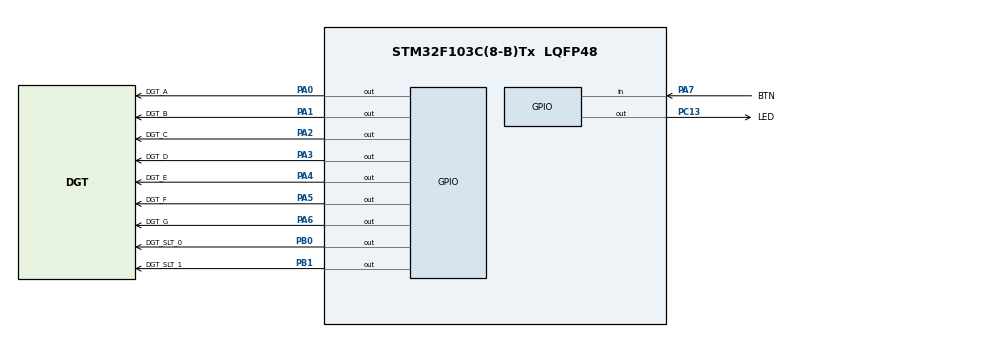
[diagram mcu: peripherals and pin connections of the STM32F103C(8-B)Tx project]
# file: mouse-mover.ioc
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Mcu.Family=STM32F1
Mcu.Name=STM32F103C(8-B)Tx
Mcu.Package=LQFP48
NVIC.PriorityGroup=NVIC_PRIORITYGROUP_4
NVIC.TIM2_IRQn=true\:0\:0\:false\:false\:true\:true\:true\:true
NVIC.TIM3_IRQn=true\:0\:0\:false\:false\:true\:true\:true\:true
PA0-WKUP.GPIO_Label=DGT_A
PA0-WKUP.Signal=GPIO_Output
PA1.GPIO_Label=DGT_B
PA1.Signal=GPIO_Output
PA13.Mode=Serial_Wire
PA13.Signal=SYS_JTMS-SWDIO
PA14.Mode=Serial_Wire
PA14.Signal=SYS_JTCK-SWCLK
PA2.GPIO_Label=DGT_C
PA2.Signal=GPIO_Output
PA3.GPIO_Label=DGT_D
PA3.Signal=GPIO_Output
PA4.GPIO_Label=DGT_E
PA4.Signal=GPIO_Output
PA5.GPIO_Label=DGT_F
PA5.Signal=GPIO_Output
PA6.GPIO_Label=DGT_G
PA6.Signal=GPIO_Output
PA7.GPIO_Label=BTN
PA7.GPIO_PuPd=GPIO_PULLUP
PA7.Signal=GPIO_Input
PB0.GPIO_Label=DGT_SLT_0
PB0.Signal=GPIO_Output
PB1.GPIO_Label=DGT_SLT_1
PB1.Signal=GPIO_Output
PC13-TAMPER-RTC.GPIO_Label=LED
PC13-TAMPER-RTC.Signal=GPIO_Output
ProjectManager.HeapSize=0x200
ProjectManager.StackSize=0x400
ProjectManager.TargetToolchain=CMake
RCC.APB1Freq_Value=8000000
RCC.APB2Freq_Value=8000000
TIM2.Period=999
TIM2.Prescaler=7999
TIM3.Period=9999
TIM3.Prescaler=7
VP_TIM2_VS_ClockSourceINT.Mode=Internal
VP_TIM3_VS_ClockSourceINT.Mode=Internal
board=custom

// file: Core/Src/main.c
/* USER CODE BEGIN Header */
/**
  ******************************************************************************
  * @file           : main.c
  * @brief          : Main program body
  ******************************************************************************
  * @attention
  *
  * Copyright (c) 2026 STMicroelectronics.
  * All rights reserved.
  *
  * This software is licensed under terms that can be found in the LICENSE file
  * in the root directory of this software component.
  * If no LICENSE file comes with this software, it is provided AS-IS.
  *
  ******************************************************************************
  */
/* USER CODE END Header */
#include "main.h"

/* USER CODE BEGIN Includes */
#include "app.h"
#include "bsp.h"
/* USER CODE END Includes */

TIM_HandleTypeDef htim2;
TIM_HandleTypeDef htim3;

void SystemClock_Config(void);
static void MX_GPIO_Init(void);
static void MX_TIM2_Init(void);
static void MX_TIM3_Init(void);

/* USER CODE BEGIN 0 */
void HAL_TIM_PeriodElapsedCallback(TIM_HandleTypeDef* htim)
{
  if (htim == &htim2)
  {
    app_countdown_tick_isr();
  }

  if (htim == &htim3)
  {
    app_display_tick_isr();
  }
}
/* USER CODE END 0 */

int main(void)
{

  /* MCU Configuration--------------------------------------------------------*/

  /* Reset of all peripherals, Initializes the Flash interface and the Systick. */
  HAL_Init();

  /* Configure the system clock */
  SystemClock_Config();

  /* Initialize all configured peripherals */
  MX_GPIO_Init();
  MX_TIM2_Init();
  MX_TIM3_Init();
  /* USER CODE BEGIN 2 */
  app_init();
  // A pending update flag would fire the first tick at once and the countdown would start one unit short.
  __HAL_TIM_CLEAR_FLAG(&htim2, TIM_FLAG_UPDATE);
  HAL_TIM_Base_Start_IT(&htim2);
  HAL_TIM_Base_Start_IT(&htim3);
  /* USER CODE END 2 */

  /* Infinite loop */
  /* USER CODE BEGIN WHILE */
  while (1)
  {
    app_run_iteration();
    /* USER CODE END WHILE */

  }
}

void SystemClock_Config(void)
{
  RCC_OscInitTypeDef RCC_OscInitStruct = {0};
  RCC_ClkInitTypeDef RCC_ClkInitStruct = {0};

  /** Initializes the RCC Oscillators according to the specified parameters
  * in the RCC_OscInitTypeDef structure.
  */
  RCC_OscInitStruct.OscillatorType = RCC_OSCILLATORTYPE_HSI;
  RCC_OscInitStruct.HSIState = RCC_HSI_ON;
  RCC_OscInitStruct.HSICalibrationValue = RCC_HSICALIBRATION_DEFAULT;
  RCC_OscInitStruct.PLL.PLLState = RCC_PLL_NONE;
  if (HAL_RCC_OscConfig(&RCC_OscInitStruct) != HAL_OK)
  {
    Error_Handler();
  }

  /** Initializes the CPU, AHB and APB buses clocks
  */
  RCC_ClkInitStruct.ClockType = RCC_CLOCKTYPE_HCLK|RCC_CLOCKTYPE_SYSCLK
                              |RCC_CLOCKTYPE_PCLK1|RCC_CLOCKTYPE_PCLK2;
  RCC_ClkInitStruct.SYSCLKSource = RCC_SYSCLKSOURCE_HSI;
  RCC_ClkInitStruct.AHBCLKDivider = RCC_SYSCLK_DIV1;
  RCC_ClkInitStruct.APB1CLKDivider = RCC_HCLK_DIV1;
  RCC_ClkInitStruct.APB2CLKDivider = RCC_HCLK_DIV1;

  if (HAL_RCC_ClockConfig(&RCC_ClkInitStruct, FLASH_LATENCY_0) != HAL_OK)
  {
    Error_Handler();
  }
}

static void MX_TIM2_Init(void)
{

  TIM_ClockConfigTypeDef sClockSourceConfig = {0};
  TIM_MasterConfigTypeDef sMasterConfig = {0};

  htim2.Instance = TIM2;
  htim2.Init.Prescaler = 7999;
  htim2.Init.CounterMode = TIM_COUNTERMODE_UP;
  htim2.Init.Period = 999;
  htim2.Init.ClockDivision = TIM_CLOCKDIVISION_DIV1;
  htim2.Init.AutoReloadPreload = TIM_AUTORELOAD_PRELOAD_DISABLE;
  if (HAL_TIM_Base_Init(&htim2) != HAL_OK)
  {
    Error_Handler();
  }
  sClockSourceConfig.ClockSource = TIM_CLOCKSOURCE_INTERNAL;
  if (HAL_TIM_ConfigClockSource(&htim2, &sClockSourceConfig) != HAL_OK)
  {
    Error_Handler();
  }
  sMasterConfig.MasterOutputTrigger = TIM_TRGO_RESET;
  sMasterConfig.MasterSlaveMode = TIM_MASTERSLAVEMODE_DISABLE;
  if (HAL_TIMEx_MasterConfigSynchronization(&htim2, &sMasterConfig) != HAL_OK)
  {
    Error_Handler();
  }

}

static void MX_TIM3_Init(void)
{

  TIM_ClockConfigTypeDef sClockSourceConfig = {0};
  TIM_MasterConfigTypeDef sMasterConfig = {0};

  htim3.Instance = TIM3;
  htim3.Init.Prescaler = 7;
  htim3.Init.CounterMode = TIM_COUNTERMODE_UP;
  htim3.Init.Period = 9999;
  htim3.Init.ClockDivision = TIM_CLOCKDIVISION_DIV1;
  htim3.Init.AutoReloadPreload = TIM_AUTORELOAD_PRELOAD_DISABLE;
  if (HAL_TIM_Base_Init(&htim3) != HAL_OK)
  {
    Error_Handler();
  }
  sClockSourceConfig.ClockSource = TIM_CLOCKSOURCE_INTERNAL;
  if (HAL_TIM_ConfigClockSource(&htim3, &sClockSourceConfig) != HAL_OK)
  {
    Error_Handler();
  }
  sMasterConfig.MasterOutputTrigger = TIM_TRGO_RESET;
  sMasterConfig.MasterSlaveMode = TIM_MASTERSLAVEMODE_DISABLE;
  if (HAL_TIMEx_MasterConfigSynchronization(&htim3, &sMasterConfig) != HAL_OK)
  {
    Error_Handler();
  }

}

static void MX_GPIO_Init(void)
{
  GPIO_InitTypeDef GPIO_InitStruct = {0};

  /* GPIO Ports Clock Enable */
  __HAL_RCC_GPIOC_CLK_ENABLE();
  __HAL_RCC_GPIOA_CLK_ENABLE();
  __HAL_RCC_GPIOB_CLK_ENABLE();

  /*Configure GPIO pin Output Level */
  HAL_GPIO_WritePin(LED_GPIO_Port, LED_Pin, GPIO_PIN_RESET);

  /*Configure GPIO pin Output Level */
  HAL_GPIO_WritePin(GPIOA, DGT_A_Pin|DGT_B_Pin|DGT_C_Pin|DGT_D_Pin
                          |DGT_E_Pin|DGT_F_Pin|DGT_G_Pin, GPIO_PIN_RESET);

  /*Configure GPIO pin Output Level */
  HAL_GPIO_WritePin(GPIOB, DGT_SLT_0_Pin|DGT_SLT_1_Pin, GPIO_PIN_RESET);

  /*Configure GPIO pin : LED_Pin */
  GPIO_InitStruct.Pin = LED_Pin;
  GPIO_InitStruct.Mode = GPIO_MODE_OUTPUT_PP;
  GPIO_InitStruct.Pull = GPIO_NOPULL;
  GPIO_InitStruct.Speed = GPIO_SPEED_FREQ_LOW;
  HAL_GPIO_Init(LED_GPIO_Port, &GPIO_InitStruct);

  /*Configure GPIO pins : DGT_A_Pin DGT_B_Pin DGT_C_Pin DGT_D_Pin
                           DGT_E_Pin DGT_F_Pin DGT_G_Pin */
  GPIO_InitStruct.Pin = DGT_A_Pin|DGT_B_Pin|DGT_C_Pin|DGT_D_Pin
                          |DGT_E_Pin|DGT_F_Pin|DGT_G_Pin;
  GPIO_InitStruct.Mode = GPIO_MODE_OUTPUT_PP;
  GPIO_InitStruct.Pull = GPIO_NOPULL;
  GPIO_InitStruct.Speed = GPIO_SPEED_FREQ_LOW;
  HAL_GPIO_Init(GPIOA, &GPIO_InitStruct);

  /*Configure GPIO pin : BTN_Pin */
  GPIO_InitStruct.Pin = BTN_Pin;
  GPIO_InitStruct.Mode = GPIO_MODE_INPUT;
  GPIO_InitStruct.Pull = GPIO_PULLUP;
  HAL_GPIO_Init(BTN_GPIO_Port, &GPIO_InitStruct);

  /*Configure GPIO pins : DGT_SLT_0_Pin DGT_SLT_1_Pin */
  GPIO_InitStruct.Pin = DGT_SLT_0_Pin|DGT_SLT_1_Pin;
  GPIO_InitStruct.Mode = GPIO_MODE_OUTPUT_PP;
  GPIO_InitStruct.Pull = GPIO_NOPULL;
  GPIO_InitStruct.Speed = GPIO_SPEED_FREQ_LOW;
  HAL_GPIO_Init(GPIOB, &GPIO_InitStruct);

}

void Error_Handler(void)
{
  /* USER CODE BEGIN Error_Handler_Debug */
  /* User can add his own implementation to report the HAL error return state */
  bsp_safe_state();  /* motor off; once started, the watchdog resets the MCU */
  __disable_irq();
  while (1)
  {
  }
  /* USER CODE END Error_Handler_Debug */
}
